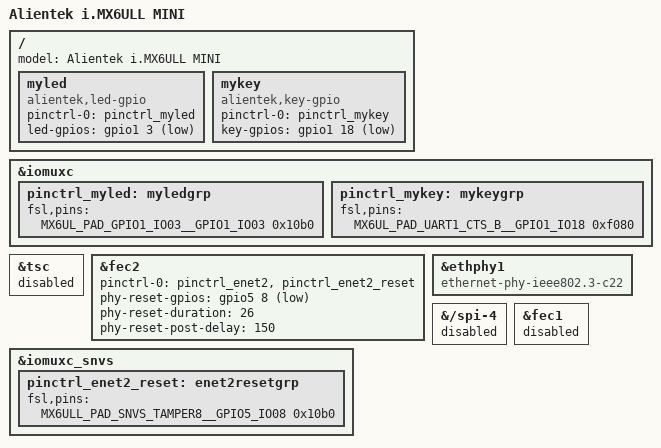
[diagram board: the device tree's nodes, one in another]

 // SPDX-License-Identifier: GPL-2.0
  /*
   * imx6ull-alientek.dts — 正点原子 i.MX6ULL MINI 板级设备树
   * 继承 NXP EVK 硬件描述, 只叠加本板差异: LED/KEY + 禁tsc让出引脚
   */
  #include "imx6ull-14x14-evk.dts"

  / {
        model = "Alientek i.MX6ULL MINI";

        /* 板载 LED: GPIO1_IO03, 低电平点亮 */
        myled {
                compatible = "alientek,led-gpio";
                pinctrl-names = "default";
                pinctrl-0 = <&pinctrl_myled>;
                led-gpios = <&gpio1 3 GPIO_ACTIVE_LOW>;
                status = "okay";
        };

        /* 板载 KEY0: GPIO1_IO18(UART1_CTS_B), 按下接地, 低有效 */
        mykey {
                compatible = "alientek,key-gpio";
                pinctrl-names = "default";
                pinctrl-0 = <&pinctrl_mykey>;
                key-gpios = <&gpio1 18 GPIO_ACTIVE_LOW>;
                status = "okay";
        };
  };

  &iomuxc {
        pinctrl_myled: myledgrp {
                fsl,pins = <
                        MX6UL_PAD_GPIO1_IO03__GPIO1_IO03        0x10b0
                >;
        };

        pinctrl_mykey: mykeygrp {
                fsl,pins = <
                        MX6UL_PAD_UART1_CTS_B__GPIO1_IO18       0xf080
                >;
        };
  };

  /* 禁用电阻触摸控制器, 把 GPIO1_IO03 让给 LED */
  &tsc {
        status = "disabled";
  };

  /* ===== 网卡: 本板 ENET2(fec2) 接 SR8201F, 非EVK的Micrel =====
   * EVK没给PHY复位, 而SR8201F需硬复位+等150ms才在MDIO应答(当年msleep(150)的病根) */
  &fec2 {
        /* EVK原有enet2引脚 + 复位脚引脚复用 */
        pinctrl-0 = <&pinctrl_enet2 &pinctrl_enet2_reset>;
        /* 硬复位PHY: GPIO5_IO8; 复位后等150ms = 当年 msleep(150) 的设备树版 */
        phy-reset-gpios = <&gpio5 8 GPIO_ACTIVE_LOW>;
        phy-reset-duration = <26>;
        phy-reset-post-delay = <150>;
  };

  /* SNVS_TAMPER8 复位脚复用成 GPIO5_IO08 (原本在spi4组里, 单独配) */
  &iomuxc_snvs {
        pinctrl_enet2_reset: enet2resetgrp {
                fsl,pins = <
                        MX6ULL_PAD_SNVS_TAMPER8__GPIO5_IO08     0x10b0
                >;
        };
  };

  /* SR8201F 是 RTL8201 兼容, 不是 Micrel — 改用通用PHY, 让内核复位后读真实ID */
  &ethphy1 {
        compatible = "ethernet-phy-ieee802.3-c22";
        /delete-property/ micrel,led-mode;
  };

  /* EVK用74HC595扩展器(spi-4节点)管PHY复位, 它的使能脚占了GPIO5_IO8——
   * 而我们要用GPIO5_IO8直接复位SR8201F, 冲突(fec2 probe报-16 EBUSY)。
   * 本板没有这颗芯片, 禁掉整个spi-4, 释放GPIO5_IO8 (呼应4.1.15时禁spi4) */
  &{/spi-4} {
        status = "disabled";
  };

  /* 本板单网口, 只用 ENET2(fec2)。ENET1(fec1)未接PHY, 禁掉免报错 */
  &fec1 {
        status = "disabled";
  };
